AUTOSAR XML (schema 4-0-3)
package /ComponentTypes
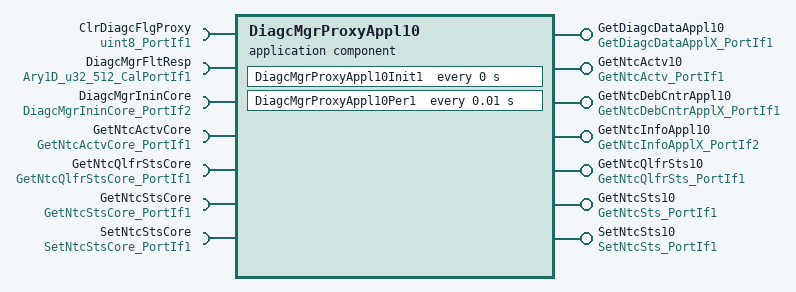
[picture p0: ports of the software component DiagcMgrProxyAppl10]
  application sw component type DiagcMgrProxyAppl10
    7 x provide port, all with server-com-spec{operation=Oper, queue-length=1}:
      GetDiagcDataAppl10: provided-interface=GetDiagcDataApplX_PortIf1
      GetNtcActv10: provided-interface=GetNtcActv_PortIf1
      GetNtcDebCntrAppl10: provided-interface=GetNtcDebCntrApplX_PortIf1
      GetNtcInfoAppl10: provided-interface=GetNtcInfoApplX_PortIf2
      GetNtcQlfrSts10: provided-interface=GetNtcQlfrSts_PortIf1
      GetNtcSts10: provided-interface=GetNtcSts_PortIf1
      SetNtcSts10: provided-interface=SetNtcSts_PortIf1
    7 x require port:
      ClrDiagcFlgProxy: nonqueued-receiver-com-spec{data-element=Val, filter=data-filter-type=ALWAYS, init-value=0}, required-interface=uint8_PortIf1
      DiagcMgrFltResp: parameter-require-com-spec{init-value=[0, 2147487488, 2147487488, 2147487488, 2147487488, 2147487488, 2147487488, 2147487488, 2147487488, 2147487488, 2147487488, 2147487488, 2147487488, 2147487488, 2147487488, 2147487488, 2147487488, 2147487488, 2147487488, 2147487488, 2147487488, 2147487488, 2147487488, 2147487488, 2147487488, 2147487488, 2147487488, 2147487488, 2147487488, 2147487488, 2147487488, 2147487488, 2147487488, 2147487488, 2147487488, 2147487488, 2147487488, 2147487488, 2147487488, 2147487488, 2147487488, 2147487488, 2147487488, 2147487488, 2147487488, 2147487488, 2147487488, 2147487488, 2147487488, 2147487488, 2147487488, 2147487488, 2147487488, 2147487488, 2147487488, 2147487488, 2147487488, 2147487488, 2147487488, 2147487488, 2147487488, 2147487488, 2147487488, 2147487488, 2147487488, 2147487488, 2147487488, 2147487488, 2147487488, 2147487488, 2147487488, 2147487488, 2147487488, 2147487488, 2147487488, 2147487488, 2147487488, 2147487488, 2147487488, 2147487488, 2147487488, 2147487488, 2147487488, 2147487488, 2147487488, 2147487488, 2147487488, 2147487488, 2147487488, 2147487488, 2147487488, 2147487488, 2147487488, 2147487488, 2147487488, 2147487488, 2147487488, 2147487488, 2147487488, 2147487488, 2147487488, 2147487488, 2147487488, 2147487488, 2147487488, 2147487488, 2147487488, 2147487488, 2147487488, 2147487488, 2147487488, 2147487488, 2147487488, 2147487488, 2147487488, 2147487488, 2147487488, 2147487488, 2147487488, 2147487488, 2147487488, 2147487488, 2147487488, 2147487488, 2147487488, 2147487488, 2147487488, 2147487488, 2147487488, 2147487488, 2147487488, 2147487488, 2147487488, 2147487488, 2147487488, 2147487488, 2147487488, 2147487488, 2147487488, 2147487488, 2147487488, 2147487488, 2147487488, 2147487488, 2147487488, 2147487488, 2147487488, 2147487488, 2147487488, 2147487488, 2147487488, 2147487488, 2147487488, 2147487488, 2147487488, 2147487488, 2147487488, 2147487488, 2147487488, 2147487488, 2147487488, 2147487488, 2147487488, 2147487488, 2147487488, 2147487488, 2147487488, 2147487488, 2147487488, 2147487488, 2147487488, 2147487488, 2147487488, 2147487488, 2147487488, 2147487488, 2147487488, 2147487488, 2147487488, 2147487488, 2147487488, 2147487488, 2147487488, 2147487488, 2147487488, 2147487488, 2147487488, 2147487488, 2147487488, 2147487488, 2147487488, 2147487488, 2147487488, 2147487488, 2147487488, 2147487488, 2147487488, 2147487488, 2147487488, 2147487488, 2147487488, 2147487488, 2147487488, 2147487488, 2147487488, 2147487488, 2147487488, 2147487488, 2147487488, 2147487488, 2147487488, 2147487488, 2147487488, 2147487488, 2147487488, 2147487488, 2147487488, 2147487488, 2147487488, 2147487488, 2147487488, 2147487488, 2147487488, 2147487488, 2147487488, 2147487488, 2147487488, 2147487488, 2147487488, 2147487488, 2147487488, 2147487488, 2147487488, 2147487488, 2147487488, 2147487488, 2147487488, 2147487488, 2147487488, 2147487488, 2147487488, 2147487488, 2147487488, 2147487488, 2147487488, 2147487488, 2147487488, 2147487488, 2147487488, 2147487488, 2147487488, 2147487488, 2147487488, 2147487488, 2147487488, 2147487488, 2147487488, 2147487488, 2147487488, 2147487488, 2147487488, 2147487488, 2147487488, 2147487488, 2147487488, 2147487488, 2147487488, 2147487488, 2147487488, 2147487488, 2147487488, 2147487488, 2147487488, 2147487488, 2147487488, 2147487488, 2147487488, 2147487488, 2147487488, 2147487488, 2147487488, 2147487488, 2147487488, 2147487488, 2147487488, 2147487488, 2147487488, 2147487488, 2147487488, 2147487488, 2147487488, 2147487488, 2147487488, 2147487488, 2147487488, 2147487488, 2147487488, 2147487488, 2147487488, 2147487488, 2147487488, 2147487488, 2147487488, 2147487488, 2147487488, 2147487488, 2147487488, 2147487488, 2147487488, 2147487488, 2147487488, 2147487488, 2147487488, 2147487488, 2147487488, 2147487488, 2147487488, 2147487488, 2147487488, 2147487488, 2147487488, 2147487488, 2147487488, 2147487488, 2147487488, 2147487488, 2147487488, 2147487488, 2147487488, 2147487488, 2147487488, 2147487488, 2147487488, 2147487488, 2147487488, 2147487488, 2147487488, 2147487488, 2147487488, 2147487488, 2147487488, 2147487488, 2147487488, 2147487488, 2147487488, 2147487488, 2147487488, 2147487488, 2147487488, 2147487488, 2147487488, 2147487488, 2147487488, 2147487488, 2147487488, 2147487488, 2147487488, 2147487488, 2147487488, 2147487488, 2147487488, 2147487488, 2147487488, 2147487488, 2147487488, 2147487488, 2147487488, 2147487488, 2147487488, 2147487488, 2147487488, 2147487488, 2147487488, 2147487488, 2147487488, 2147487488, 2147487488, 2147487488, 2147487488, 2147487488, 2147487488, 2147487488, 2147487488, 2147487488, 2147487488, 2147487488, 2147487488, 2147487488, 2147487488, 2147487488, 2147487488, 2147487488, 2147487488, 2147487488, 2147487488, 2147487488, 2147487488, 2147487488, 2147487488, 2147487488, 2147487488, 2147487488, 2147487488, 2147487488, 2147487488, 2147487488, 2147487488, 2147487488, 2147487488, 2147487488, 2147487488, 2147487488, 2147487488, 2147487488, 2147487488, 2147487488, 2147487488, 2147487488, 2147487488, 2147487488, 2147487488, 2147487488, 2147487488, 2147487488, 2147487488, 2147487488, 2147487488, 2147487488, 2147487488, 2147487488, 2147487488, 2147487488, 2147487488, 2147487488, 2147487488, 2147487488, 2147487488, 2147487488, 2147487488, 2147487488, 2147487488, 2147487488, 2147487488, 2147487488, 2147487488, 2147487488, 2147487488, 2147487488, 2147487488, 2147487488, 2147487488, 2147487488, 2147487488, 2147487488, 2147487488, 2147487488, 2147487488, 2147487488, 2147487488, 2147487488, 2147487488, 2147487488, 2147487488, 2147487488, 2147487488, 2147487488, 2147487488, 2147487488, 2147487488, 2147487488, 2147487488, 2147487488, 2147487488, 2147487488, 2147487488, 2147487488, 2147487488, 2147487488, 2147487488, 2147487488, 2147487488, 2147487488, 2147487488, 2147487488, 2147487488, 2147487488, 2147487488, 2147487488, 2147487488, 2147487488, 2147487488, 2147487488, 2147487488, 2147487488, 2147487488, 2147487488, 2147487488, 2147487488, 2147487488, 2147487488, 2147487488, 2147487488, 2147487488, 2147487488, 2147487488, 2147487488, 2147487488, 2147487488, 2147487488, 2147487488, 2147487488, 2147487488], parameter=Ary1D}, required-interface=Ary1D_u32_512_CalPortIf1
      DiagcMgrIninCore: required-interface=DiagcMgrIninCore_PortIf2
      GetNtcActvCore: required-interface=GetNtcActvCore_PortIf1
      GetNtcQlfrStsCore: required-interface=GetNtcQlfrStsCore_PortIf1
      GetNtcStsCore: required-interface=GetNtcStsCore_PortIf1
      SetNtcStsCore: required-interface=SetNtcStsCore_PortIf1
    behavior DiagcMgrProxyAppl10_InternalBehavior
      exclusive area DiagcMgrProxyAppl10
      ar-typed-per-instance-memorys:
        5 x data:
          DiagcData10: sw-calibration-access=READ-ONLY, type=DiagcDataRec1
          DiagcMgrNtcInfo10Ary: type=Ary1D_NtcInfoRec4_DiagcMgrProxyAppl10
          DiagcMgrNtcInfo10DebCntrAry: type=Ary1D_s16_DiagcMgrProxyAppl10
          PrevClrNtcFlg10: sw-calibration-access=READ-ONLY, type=uint8
          ProxySetNtcData10: sw-calibration-access=READ-ONLY, type=DiagcDataRec1
      timing event DiagcMgrProxyAppl10Init1_InitEvent: start-on-event=DiagcMgrProxyAppl10Init1, period=0
      timing event TMT_DiagcMgrProxyAppl10Per1: start-on-event=DiagcMgrProxyAppl10Per1, period=0.01
      7 x operation invoked event:
        OIT_GetDiagcDataAppl10_Oper_GetDiagcDataAppl10_Oper: start-on-event=GetDiagcDataAppl10_Oper, operation=GetDiagcDataAppl10.Oper
        OIT_GetNtcActv10_Oper_GetNtcActv10_Oper: start-on-event=GetNtcActv10_Oper, operation=GetNtcActv10.Oper
        OIT_GetNtcDebCntrAppl10_Oper_GetNtcDebCntrAppl10_Oper: start-on-event=GetNtcDebCntrAppl10_Oper, operation=GetNtcDebCntrAppl10.Oper
        OIT_GetNtcInfoAppl10_Oper_GetNtcInfoAppl10_Oper: start-on-event=GetNtcInfoAppl10_Oper, operation=GetNtcInfoAppl10.Oper
        OIT_GetNtcQlfrSts10_Oper_GetNtcQlfrSts10_Oper: start-on-event=GetNtcQlfrSts10_Oper, operation=GetNtcQlfrSts10.Oper
        OIT_GetNtcSts10_Oper_GetNtcSts10_Oper: start-on-event=GetNtcSts10_Oper, operation=GetNtcSts10.Oper
        OIT_SetNtcSts10_Oper_SetNtcSts10_Oper: start-on-event=SetNtcSts10_Oper, operation=SetNtcSts10.Oper
      9 x runnable:
        DiagcMgrProxyAppl10Init1
          sync call SC_DiagcMgrIninCore_Oper: operation=DiagcMgrIninCore.Oper, timeout=0
        DiagcMgrProxyAppl10Per1: can-enter-exclusive-area=DiagcMgrProxyAppl10
          data-receive-point-by-arguments:
            access REC_ClrNtcFlg_Val: accessed-variable=ClrDiagcFlgProxy.Val
        GetDiagcDataAppl10_Oper: can-enter-exclusive-area=DiagcMgrProxyAppl10
        GetNtcActv10_Oper: can-be-invoked-concurrently=true
          sync call SC_GetNtcActvCore_Oper: operation=GetNtcActvCore.Oper, timeout=0
        GetNtcDebCntrAppl10_Oper
        GetNtcInfoAppl10_Oper
        GetNtcQlfrSts10_Oper: can-be-invoked-concurrently=true
          sync call SC_GetNtcQlfrStsCore_Oper: operation=GetNtcQlfrStsCore.Oper, timeout=0
        GetNtcSts10_Oper: can-be-invoked-concurrently=true
          sync call SC_GetNtcStsCore_Oper: operation=GetNtcStsCore.Oper, timeout=0
        SetNtcSts10_Oper: can-be-invoked-concurrently=true
          sync call SC_SetNtcStsCore_Oper: operation=SetNtcStsCore.Oper, timeout=0
  swc implementation DiagcMgrProxyAppl10_Implementation: behavior=DiagcMgrProxyAppl10_InternalBehavior
    code-descriptors:
      code Default: artifact-descriptors=autosar-engineering-object={short-label=Default, category=SWSRC}
